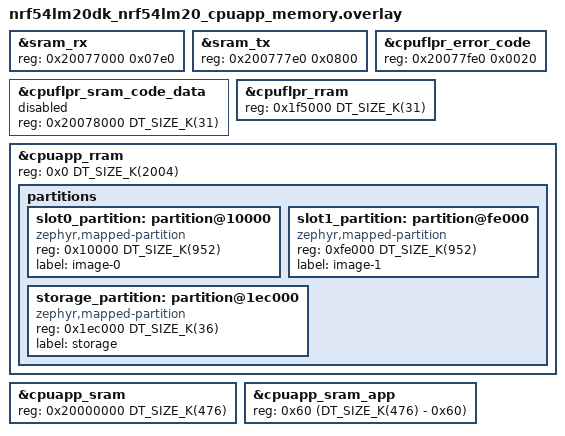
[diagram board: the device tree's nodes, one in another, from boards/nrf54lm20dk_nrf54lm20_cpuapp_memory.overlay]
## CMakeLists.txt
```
#
# Copyright (c) 2025 Nordic Semiconductor ASA
#
# SPDX-License-Identifier: LicenseRef-Nordic-5-Clause
#

cmake_minimum_required(VERSION 3.20.0)

find_package(Zephyr REQUIRED HINTS $ENV{ZEPHYR_BASE})
project(hpf_app_trap_handler)

target_sources(app PRIVATE src/main.c)
```

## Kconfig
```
#
# Copyright (c) 2025 Nordic Semiconductor ASA
#
# SPDX-License-Identifier: LicenseRef-Nordic-5-Clause
#

config FLASH
	default y if DT_HAS_JEDEC_NOR_ENABLED

config FLASH_PAGE_LAYOUT
	default y if DT_HAS_JEDEC_NOR_ENABLED

source "Kconfig.zephyr"
```

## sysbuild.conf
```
#
# Copyright (c) 2025 Nordic Semiconductor ASA
#
# SPDX-License-Identifier: LicenseRef-Nordic-5-Clause
#

SB_CONFIG_VPR_LAUNCHER=n
SB_CONFIG_HPF=y
SB_CONFIG_HPF_MSPI=y

# Enable HPF developer mode to disable CI errors.
# It is related to rebuilding the asm part after enabling ASSERT.
SB_CONFIG_HPF_DEVELOPER_MODE=y
```

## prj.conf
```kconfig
#
# Copyright (c) 2025 Nordic Semiconductor ASA
#
# SPDX-License-Identifier: LicenseRef-Nordic-5-Clause
#

CONFIG_TEST=y
CONFIG_ZTEST=y
CONFIG_MAIN_STACK_SIZE=2048
CONFIG_ZTEST_STACK_SIZE=4096
```

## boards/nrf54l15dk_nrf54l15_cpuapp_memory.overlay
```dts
/*
 * Copyright (c) 2025 Nordic Semiconductor ASA
 *
 * SPDX-License-Identifier: LicenseRef-Nordic-5-Clause
 */

&sram_rx {
	reg = <0x20039000 0x07f0>;
};

&sram_tx {
	reg = <0x200397f0 0x07f0>;
};

&cpuflpr_error_code {
	reg = <0x20039fe0 0x0020>; /* 32bytes */
};

&cpuflpr_sram_code_data {
	reg = <0x2003a000 DT_SIZE_K(24)>;
	ranges = <0x0 0x2003a000 0x6000>;
	status = "reserved";
};

&cpuflpr_rram {
	reg = <0x177000 DT_SIZE_K(24)>;
	ranges = <0x0 0x177000 DT_SIZE_K(24)>;
};

&cpuapp_rram {
	reg = <0x0 DT_SIZE_K(1500)>;
	ranges = <0x0 0x0 DT_SIZE_K(1500)>;
	#address-cells = <1>;
	#size-cells = <1>;
};

&cpuapp_sram {
	reg = <0x20000000 DT_SIZE_K(228)>;
	ranges = <0x0 0x20000000 0x39000>;
};

&cpuapp_sram_app {
	reg = <0x60 (DT_SIZE_K(228) - 0x60)>;
};
```

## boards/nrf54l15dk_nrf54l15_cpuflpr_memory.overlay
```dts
/*
 * Copyright (c) 2025 Nordic Semiconductor ASA
 *
 * SPDX-License-Identifier: LicenseRef-Nordic-5-Clause
 */

&sram_tx {
	reg = <0x20039000 0x07f0>;
};

&sram_rx {
	reg = <0x200397f0 0x07f0>;
};

&cpuflpr_error_code {
	reg = <0x20039fe0 0x0020>; /* 32bytes */
};

&cpuflpr_rram {
	reg = <0x177000 DT_SIZE_K(24)>;
	ranges = <0x0 0x177000 DT_SIZE_K(24)>;
};

&cpuflpr_code_partition {
	reg = <0x0 DT_SIZE_K(24)>;
};

&cpuflpr_sram {
	reg = <0x2003a000 DT_SIZE_K(24)>;
	ranges = <0x0 0x2003a000 0x6000>;
};
```

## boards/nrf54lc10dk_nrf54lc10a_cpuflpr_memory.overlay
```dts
/*
 * Copyright (c) 2026 Nordic Semiconductor ASA
 *
 * SPDX-License-Identifier: LicenseRef-Nordic-5-Clause
 */

&sram_tx {
	reg = <0x20028c00 0x07e0>;
};

&sram_rx {
	reg = <0x200293f0 0x07e0>;
};

&cpuflpr_error_code {
	reg = <0x20029be0 0x0020>; /* 32 bytes */
};

&cpuflpr_rram {
	reg = <0xf7000 DT_SIZE_K(24)>;
	ranges = <0x0 0xf7000 DT_SIZE_K(24)>;
};

&cpuflpr_code_partition {
	reg = <0x0 DT_SIZE_K(24)>;
};

&cpuflpr_sram {
	reg = <0x20029c00 DT_SIZE_K(24)>;
	ranges = <0x0 0x20029c00 DT_SIZE_K(24)>;
};
```

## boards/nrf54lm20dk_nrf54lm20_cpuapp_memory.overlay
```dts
/*
 * Copyright (c) 2026 Nordic Semiconductor ASA
 *
 * SPDX-License-Identifier: LicenseRef-Nordic-5-Clause
 */

/delete-node/ &slot0_partition;
/delete-node/ &slot1_partition;
/delete-node/ &storage_partition;

&sram_rx {
	reg = <0x20077000 0x07e0>;
};

&sram_tx {
	reg = <0x200777e0 0x0800>;
};

&cpuflpr_error_code {
	reg = <0x20077fe0 0x0020>; /* 32bytes */
};

&cpuflpr_sram_code_data {
	reg = <0x20078000 DT_SIZE_K(31)>;
	ranges = <0x0 0x20078000 DT_SIZE_K(31)>;
	status = "reserved";
};

&cpuflpr_rram {
	reg = <0x1f5000 DT_SIZE_K(31)>;
	ranges = <0x0 0x1f5000 DT_SIZE_K(31)>;
};

&cpuapp_rram {
	reg = <0x0 DT_SIZE_K(2004)>;
	ranges = <0x0 0x0 DT_SIZE_K(2004)>;
	#address-cells = <1>;
	#size-cells = <1>;

	partitions {
		slot0_partition: partition@10000 {
			compatible = "zephyr,mapped-partition";
			reg = <0x10000 DT_SIZE_K(952)>;
			label = "image-0";
		};

		slot1_partition: partition@fe000 {
			compatible = "zephyr,mapped-partition";
			reg = <0xfe000 DT_SIZE_K(952)>;
			label = "image-1";
		};

		storage_partition: partition@1ec000 {
			compatible = "zephyr,mapped-partition";
			reg = <0x1ec000 DT_SIZE_K(36)>;
			label = "storage";
		};
	};
};

&cpuapp_sram {
	reg = <0x20000000 DT_SIZE_K(476)>;
	ranges = <0x0 0x20000000 DT_SIZE_K(476)>;
};

&cpuapp_sram_app {
	reg = <0x60 (DT_SIZE_K(476) - 0x60)>;
};
```

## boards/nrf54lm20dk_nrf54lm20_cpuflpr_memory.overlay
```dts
/*
 * Copyright (c) 2026 Nordic Semiconductor ASA
 *
 * SPDX-License-Identifier: LicenseRef-Nordic-5-Clause
 */

&sram_tx {
	reg = <0x20077000 0x07e0>;
};

&sram_rx {
	reg = <0x200777e0 0x0800>;
};

&cpuflpr_error_code {
	reg = <0x20077fe0 0x0020>; /* 32bytes */
};

&cpuflpr_rram {
	reg = <0x1f5000 DT_SIZE_K(31)>;
	ranges = <0x0 0x1f5000 DT_SIZE_K(31)>;
};

&cpuflpr_code_partition {
	reg = <0x0 DT_SIZE_K(31)>;
};

&cpuflpr_sram {
	reg = <0x20078000 DT_SIZE_K(31)>;
	ranges = <0x0 0x20078000 DT_SIZE_K(31)>;
};
```

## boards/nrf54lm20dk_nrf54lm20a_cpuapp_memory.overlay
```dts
/*
 * Copyright (c) 2026 Nordic Semiconductor ASA
 *
 * SPDX-License-Identifier: LicenseRef-Nordic-5-Clause
 */

/delete-node/ &slot0_partition;
/delete-node/ &slot1_partition;
/delete-node/ &storage_partition;

&sram_rx {
	reg = <0x20077000 0x07e0>;
};

&sram_tx {
	reg = <0x200777e0 0x0800>;
};

&cpuflpr_error_code {
	reg = <0x20077fe0 0x0020>; /* 32bytes */
};

&cpuflpr_sram_code_data {
	reg = <0x20078000 DT_SIZE_K(31)>;
	ranges = <0x0 0x20078000 DT_SIZE_K(31)>;
	status = "reserved";
};

&cpuflpr_rram {
	reg = <0x1f5000 DT_SIZE_K(31)>;
	ranges = <0x0 0x1f5000 DT_SIZE_K(31)>;
};

&cpuapp_rram {
	reg = <0x0 DT_SIZE_K(2004)>;
	ranges = <0x0 0x0 DT_SIZE_K(2004)>;
	#address-cells = <1>;
	#size-cells = <1>;

	partitions {
		slot0_partition: partition@10000 {
			label = "image-0";
			reg = <0x10000 DT_SIZE_K(952)>;
		};

		slot1_partition: partition@fe000 {
			label = "image-1";
			reg = <0xfe000 DT_SIZE_K(952)>;
		};

		storage_partition: partition@1ec000 {
			label = "storage";
			reg = <0x1ec000 DT_SIZE_K(36)>;
		};
	};
};

&cpuapp_sram {
	reg = <0x20000000 DT_SIZE_K(476)>;
	ranges = <0x0 0x20000000 DT_SIZE_K(476)>;
};
```

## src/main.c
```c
/*
 * Copyright (c) 2025 Nordic Semiconductor ASA
 *
 * SPDX-License-Identifier: LicenseRef-Nordic-5-Clause
 */

#include <zephyr/device.h>
#include <zephyr/drivers/mspi.h>
#include <zephyr/drivers/mspi_emul.h>
#include <zephyr/ztest.h>

#define MSPI_BUS_NODE DT_NODELABEL(hpf_mspi)

#if !IS_ENABLED(CONFIG_DT_HAS_ZEPHYR_EMUL_DEVICE_MSPI_ENABLED)
static const struct device *mspi_devices[] = {
	DT_FOREACH_CHILD_STATUS_OKAY_SEP(MSPI_BUS_NODE, DEVICE_DT_GET, (,))
};
#endif

static struct mspi_dev_cfg device_cfg[] = {
	DT_FOREACH_CHILD_STATUS_OKAY_SEP(MSPI_BUS_NODE, MSPI_DEVICE_CONFIG_DT, (,))
};

ZTEST(hpf_trap_handler, test_trap_handler)
{
	int ret = 0;
	const struct device *mspi_bus = DEVICE_DT_GET(MSPI_BUS_NODE);
	const struct mspi_dev_id dev_id = {
		.dev_idx = 0xFF,
	};

	zassert_true(device_is_ready(mspi_bus), "mspi_bus is not ready");
#if !IS_ENABLED(CONFIG_DT_HAS_ZEPHYR_EMUL_DEVICE_MSPI_ENABLED)
	zassert_true(device_is_ready(mspi_devices[0]), "mspi_device is not ready");
#endif
	/* Push wrong device id to trigger assert on flpr app side */
	ret = mspi_dev_config(mspi_bus, &dev_id, MSPI_DEVICE_CONFIG_ALL, &device_cfg[0]);
	zassert_equal(ret, -ETIMEDOUT, "Assert not triggered?");
}

ZTEST_SUITE(hpf_trap_handler, NULL, NULL, NULL, NULL, NULL);
```
